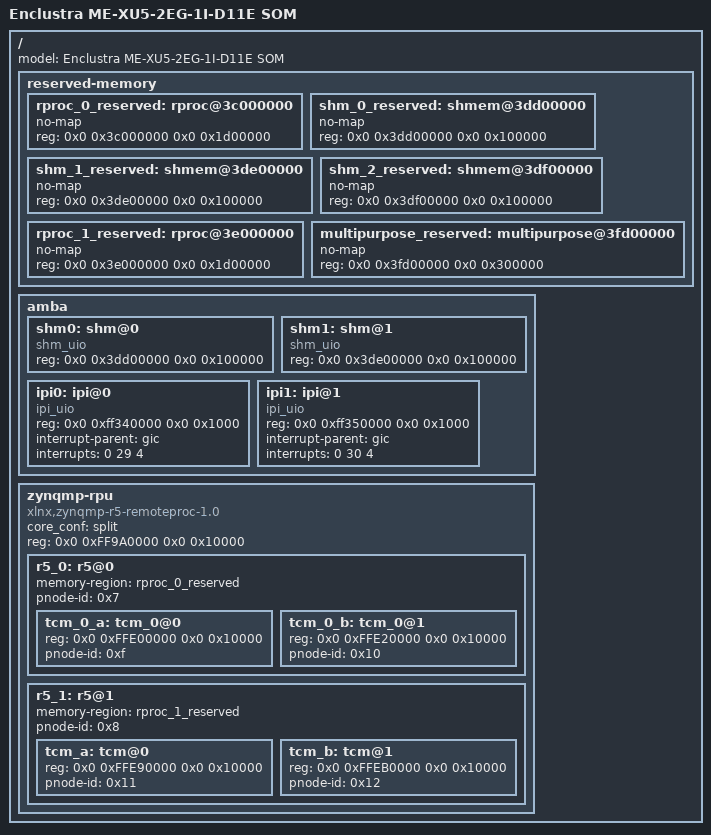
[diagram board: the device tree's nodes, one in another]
/include/ "system-conf.dtsi"
/ {
	model = "Enclustra ME-XU5-2EG-1I-D11E SOM";

	reserved-memory {
		#address-cells = <2>;
		#size-cells = <2>;
		ranges;
		
		/* Reserved memory for R5_0: 29MB */
		rproc_0_reserved: rproc@3c000000 {
			no-map;
			reg = <0x0 0x3c000000 0x0 0x1d00000>;
		};

		/* Shared memory A53 - R5_0: 1MB */
		shm_0_reserved: shmem@3dd00000 {
			no-map;
			reg = <0x0 0x3dd00000 0x0 0x100000>;
		};		

		/* Shared memory A53 - R5_1: 1MB */
		shm_1_reserved: shmem@3de00000 {
			no-map;
			reg = <0x0 0x3de00000 0x0 0x100000>;
		};	

		/* Shared memory R5_0 - R5_1: 1MB */
		shm_2_reserved: shmem@3df00000 {
			no-map;
			reg = <0x0 0x3df00000 0x0 0x100000>;
		};	

		/* Reserved memory for R5_1: 29MB */
		rproc_1_reserved: rproc@3e000000 {
			no-map;
			reg = <0x0 0x3e000000 0x0 0x1d00000>;
		};

		/* Multipurpose memory: 3MB */
		multipurpose_reserved: multipurpose@3fd00000 {
			no-map;
			reg = <0x0 0x3fd00000 0x0 0x300000>;
		};

	};

	amba {

		/* Shared memory between A53 - R5_0 */
		shm0: shm@0 {
			compatible = "shm_uio";
			reg = <0x0 0x3dd00000 0x0 0x100000>;
		};

		/* Shared memory between A53 - R5_1 */
		shm1: shm@1 {
			compatible = "shm_uio";
			reg = <0x0 0x3de00000 0x0 0x100000>;
		};

		/* Define IPI Ch7 for the IPC between A53 - R5_0 */
		ipi0: ipi@0 {
			compatible = "ipi_uio";
			reg = <0x0 0xff340000 0x0 0x1000>;
			interrupt-parent = <&gic>;
			interrupts = <0 29 4>;
		};

		/* Define IPI Ch8 for the IPC between A53 - R5_1 */
		ipi1: ipi@1 {
			compatible = "ipi_uio";
			reg = <0x0 0xff350000 0x0 0x1000>;
			interrupt-parent = <&gic>;
			interrupts = <0 30 4>;
		};

	};

	zynqmp-rpu {
		compatible = "xlnx,zynqmp-r5-remoteproc-1.0";
		#address-cells = <2>;
		#size-cells = <2>;
		ranges;
		core_conf = "split";
		reg = <0x0 0xFF9A0000 0x0 0x10000>;

		r5_0: r5@0 {
			#address-cells = <2>;
			#size-cells = <2>;
			ranges;
			memory-region = <&rproc_0_reserved>;
			pnode-id = <0x7>;
			tcm_0_a: tcm_0@0 {
				reg = <0x0 0xFFE00000 0x0 0x10000>;
				pnode-id = <0xf>;
			};
			tcm_0_b: tcm_0@1 {
				reg = <0x0 0xFFE20000 0x0 0x10000>;
				pnode-id = <0x10>;
			};
		};

		r5_1: r5@1 {
			#address-cells = <2>;
			#size-cells = <2>;
			ranges;
			memory-region = <&rproc_1_reserved>;
			pnode-id = <0x8>;
			tcm_a: tcm@0 {
				reg = <0x0 0xFFE90000 0x0 0x10000>;
				pnode-id = <0x11>;
			};
			tcm_b: tcm@1 {
				reg = <0x0 0xFFEB0000 0x0 0x10000>;
				pnode-id = <0x12>;
			};
		};
   	};

};

#include "zynqmp_enclustra_common.dtsi"
#include "zynqmp_enclustra_mercury_pe1.dtsi"
#include "zynqmp_enclustra_mercury_xu5.dtsi"
